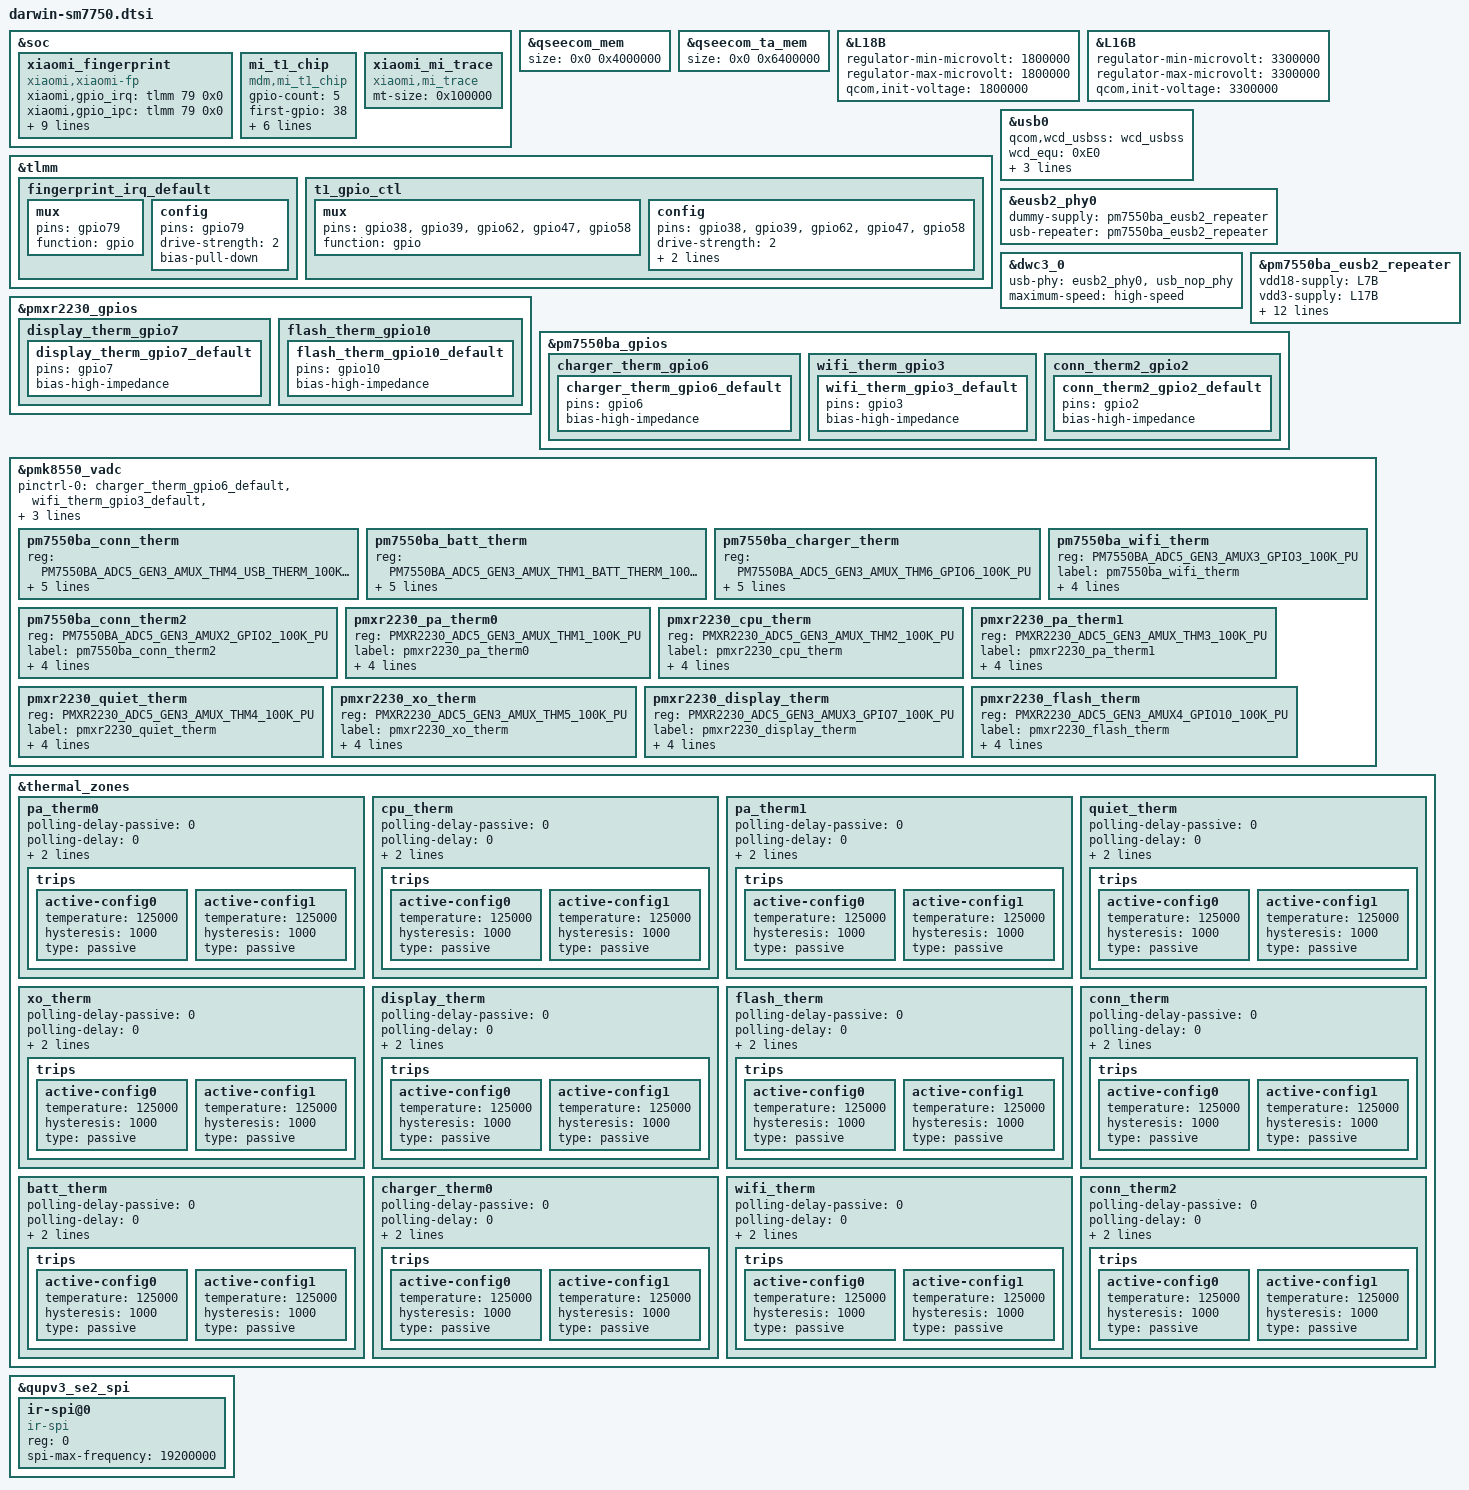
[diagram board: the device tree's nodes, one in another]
/*
  this file is for attribution only of darwin
  And public attribution of xiaomi platforms(like darwin and so on)
*/
#include "darwin-pinctrl.dtsi"
#include "sm7750-xiaomi-common.dtsi"
#include "darwin-charger-common.dtsi"
#include "kera_ufs2.dtsi"
#include <dt-bindings/iio/qcom,spmi-adc5-gen3-pmxr2230.h>

&soc {
    xiaomi_fingerprint {
        compatible = "xiaomi,xiaomi-fp";
        xiaomi,gpio_irq = <&tlmm 79 0x0>;
        xiaomi,gpio_ipc = <&tlmm 79 0x0>;
        xiaomi,vendor_names = "DARWIN_n2_132_431";
        intr2-pin-enable;
        intr2-side-config = "TIC";
        intr2-default-electrical = <1 1>;
        fp_3v3_vreg-supply = <&L16B>;
        fp_1v8_vreg-supply = <&L18B>;
        netlink-event = <25>;
        sensor-loc = <480 1906 719 2165>;
        pinctrl-names = "irq_default";
        pinctrl-0 = <&fingerprint_irq_default>;
        status = "ok";
    };

    mi_t1_chip {
        compatible = "mdm,mi_t1_chip";
        gpio-count = <5>;
        first-gpio = <38>;
        mi-t1-gpio-1 = <&tlmm 38 0x0>;
        mi-t1-gpio-2 = <&tlmm 39 0x0>;
        mi-t1-gpio-3 = <&tlmm 62 0x0>;
        mi-t1-gpio-4 = <&tlmm 47 0x0>;
        mi-t1-gpio-5 = <&tlmm 58 0x0>;
        pinctrl-0 = <&t1_gpio_ctl>;
    };
};

&qseecom_mem {
		size = <0x0 0x4000000>;
};

&qseecom_ta_mem {
		size = <0x0 0x6400000>;
};

&L18B {
    regulator-min-microvolt = <1800000>;
    regulator-max-microvolt = <1800000>;
    qcom,init-voltage = <1800000>;
};

&L16B {
    regulator-min-microvolt = <3300000>;
    regulator-max-microvolt = <3300000>;
    qcom,init-voltage = <3300000>;
};

&tlmm {
    fingerprint_irq_default: fingerprint_irq_default {
        mux {
            pins = "gpio79";
            function = "gpio";
        };
        config {
            pins = "gpio79";
            drive-strength = <2>;
            bias-pull-down;
        };
    };

    /*t1s gpio config*/
    t1_gpio_ctl: t1_gpio_ctl {
        mux {
            pins = "gpio38", "gpio39","gpio62", "gpio47", "gpio58";
            function = "gpio";
        };
        config {
            pins = "gpio38", "gpio39","gpio62", "gpio47", "gpio58";
            drive-strength = <2>;
            bias-disable;
            output-enable;
        };
    };
};

&usb0 {
	qcom,wcd_usbss = <&wcd_usbss>;
	wcd_equ = <0xE0>;
	wcd_equ_global = <0xF0>;
	wcd_equ_host = <0xC0>;
	maximum_speed = "high-speed";
};

&eusb2_phy0 {
	dummy-supply = <&pm7550ba_eusb2_repeater>;
	usb-repeater = <&pm7550ba_eusb2_repeater>;
};

&dwc3_0 {
	usb-phy = <&eusb2_phy0>, <&usb_nop_phy>;
	maximum-speed = "high-speed";
};

&pm7550ba_eusb2_repeater {
	vdd18-supply = <&L7B>;
	vdd3-supply = <&L17B>;
	status = "ok";
	en-carwith = <0>;
	en-storage = <1>;
	qcom,host-param-override-seq =
		<0x00 0x50
		0x0c 0x51
		0x03 0x52
		0x07 0x53
		0x01 0x54
		0x01 0x55
		0x00 0x56
		0x06 0x57
		0x02 0x58
		0x00 0x59
		0x03 0x5a
		0x02 0x5b>;
	qcom,param-override-seq-host-ms =
		<0x00 0x50
		0x00 0x51
		0x01 0x52
		0x07 0x53
		0x05 0x54
		0x00 0x55
		0x03 0x56
		0x00 0x57
		0x02 0x58
		0x00 0x59
		0x03 0x5a
		0x02 0x5b>;
	qcom,param-override-seq =
		<0x00 0x50
		0x0A 0x51
		0x01 0x52
		0x07 0x53
		0x03 0x54
		0x03 0x55
		0x00 0x56
		0x07 0x57
		0x02 0x58
		0x03 0x59
		0x01 0x5a
		0x02 0x5b>;
	qcom,param-override-seq-factory =
		<0x00 0x50
		0x07 0x51
		0x01 0x52
		0x01 0x53
		0x03 0x54
		0x03 0x55
		0x00 0x56
		0x05 0x57
		0x02 0x58
		0x03 0x59
		0x01 0x5a
		0x02 0x5b>;
	qcom,param-override-seq-car =
		<0x00 0x50
		0x07 0x51
		0x01 0x52
		0x01 0x53
		0x03 0x54
		0x03 0x55
		0x00 0x56
		0x05 0x57
		0x02 0x58
		0x03 0x59
		0x01 0x5a
		0x02 0x5b>;
};

&pmxr2230_gpios {
    display_therm_gpio7 {
        display_therm_gpio7_default: display_therm_gpio7_default {
            pins = "gpio7";
            bias-high-impedance;
        };
    };
    flash_therm_gpio10 {
        flash_therm_gpio10_default: flash_therm_gpio10_default {
            pins = "gpio10";
            bias-high-impedance;
        };
    };
};
&pm7550ba_gpios {
    charger_therm_gpio6 {
        charger_therm_gpio6_default: charger_therm_gpio6_default {
            pins = "gpio6";
            bias-high-impedance;
        };
    };
    wifi_therm_gpio3 {
        wifi_therm_gpio3_default: wifi_therm_gpio3_default {
            pins = "gpio3";
            bias-high-impedance;
        };
    };
    conn_therm2_gpio2 {
        conn_therm2_gpio2_default: conn_therm2_gpio2_default {
            pins = "gpio2";
            bias-high-impedance;
        };
    };
};
&pmk8550_vadc {
    pinctrl-names = "default";
    pinctrl-0 = <&charger_therm_gpio6_default &wifi_therm_gpio3_default &conn_therm2_gpio2_default &flash_therm_gpio10_default &display_therm_gpio7_default>;
    pm7550ba_conn_therm {
            reg = <PM7550BA_ADC5_GEN3_AMUX_THM4_USB_THERM_100K_PU>;
            label = "pm7550ba_conn_therm";
            qcom,ratiometric;
            qcom,hw-settle-time = <200>;
            qcom,pre-scaling = <1 1>;
            qcom,adc-tm-type = <1>;
    };
    pm7550ba_batt_therm {
            reg = <PM7550BA_ADC5_GEN3_AMUX_THM1_BATT_THERM_100K_PU>;
            label = "pm7550ba_batt_therm";
            qcom,ratiometric;
            qcom,hw-settle-time = <200>;
            qcom,pre-scaling = <1 1>;
            qcom,adc-tm-type = <1>;
    };
    pm7550ba_charger_therm {
        reg = <PM7550BA_ADC5_GEN3_AMUX_THM6_GPIO6_100K_PU>;
        label = "pm7550ba_charger_therm";
        qcom,ratiometric;
        qcom,hw-settle-time = <200>;
        qcom,pre-scaling = <1 1>;
        qcom,adc-tm-type = <1>;
    };
    pm7550ba_wifi_therm {
        reg = <PM7550BA_ADC5_GEN3_AMUX3_GPIO3_100K_PU>;
        label = "pm7550ba_wifi_therm";
        qcom,ratiometric;
        qcom,hw-settle-time = <200>;
        qcom,pre-scaling = <1 1>;
        qcom,adc-tm-type = <1>;
    };
    pm7550ba_conn_therm2 {
        reg = <PM7550BA_ADC5_GEN3_AMUX2_GPIO2_100K_PU>;
        label = "pm7550ba_conn_therm2";
        qcom,ratiometric;
        qcom,hw-settle-time = <200>;
        qcom,pre-scaling = <1 1>;
        qcom,adc-tm-type = <1>;
    };
    pmxr2230_pa_therm0 {
        reg = <PMXR2230_ADC5_GEN3_AMUX_THM1_100K_PU>;
        label = "pmxr2230_pa_therm0";
        qcom,ratiometric;
        qcom,hw-settle-time = <200>;
        qcom,pre-scaling = <1 1>;
        qcom,adc-tm-type = <1>;
    };
    pmxr2230_cpu_therm {
        reg = <PMXR2230_ADC5_GEN3_AMUX_THM2_100K_PU>;
        label = "pmxr2230_cpu_therm";
        qcom,ratiometric;
        qcom,hw-settle-time = <200>;
        qcom,pre-scaling = <1 1>;
        qcom,adc-tm-type = <1>;
    };
    pmxr2230_pa_therm1 {
        reg = <PMXR2230_ADC5_GEN3_AMUX_THM3_100K_PU>;
        label = "pmxr2230_pa_therm1";
        qcom,ratiometric;
        qcom,hw-settle-time = <200>;
        qcom,pre-scaling = <1 1>;
        qcom,adc-tm-type = <1>;
    };
    pmxr2230_quiet_therm {
        reg = <PMXR2230_ADC5_GEN3_AMUX_THM4_100K_PU>;
        label = "pmxr2230_quiet_therm";
        qcom,ratiometric;
        qcom,hw-settle-time = <200>;
        qcom,pre-scaling = <1 1>;
        qcom,adc-tm-type = <1>;
    };
    pmxr2230_xo_therm {
        reg = <PMXR2230_ADC5_GEN3_AMUX_THM5_100K_PU>;
        label = "pmxr2230_xo_therm";
        qcom,ratiometric;
        qcom,hw-settle-time = <200>;
        qcom,pre-scaling = <1 1>;
        qcom,adc-tm-type = <1>;
    };
    pmxr2230_display_therm {
        reg = <PMXR2230_ADC5_GEN3_AMUX3_GPIO7_100K_PU>;
        label = "pmxr2230_display_therm";
        qcom,ratiometric;
        qcom,hw-settle-time = <200>;
        qcom,pre-scaling = <1 1>;
        qcom,adc-tm-type = <1>;
    };
    pmxr2230_flash_therm {
        reg = <PMXR2230_ADC5_GEN3_AMUX4_GPIO10_100K_PU>;
        label = "pmxr2230_flash_therm";
        qcom,ratiometric;
        qcom,hw-settle-time = <200>;
        qcom,pre-scaling = <1 1>;
        qcom,adc-tm-type = <1>;
    };
};
&thermal_zones {
    pa_therm0 {
        polling-delay-passive = <0>;
        polling-delay = <0>;
        thermal-sensors = <&pmk8550_vadc PMXR2230_ADC5_GEN3_AMUX_THM1_100K_PU>;
        trips {
            active-config0 {
                temperature = <125000>;
                hysteresis = <1000>;
                type = "passive";
            };
            active-config1 {
                temperature = <125000>;
                hysteresis = <1000>;
                type = "passive";
            };
        };
    };
    cpu_therm {
        polling-delay-passive = <0>;
        polling-delay = <0>;
        thermal-sensors = <&pmk8550_vadc PMXR2230_ADC5_GEN3_AMUX_THM2_100K_PU>;
        trips {
            active-config0 {
                temperature = <125000>;
                hysteresis = <1000>;
                type = "passive";
            };
            active-config1 {
                temperature = <125000>;
                hysteresis = <1000>;
                type = "passive";
            };
        };
    };
    pa_therm1 {
        polling-delay-passive = <0>;
        polling-delay = <0>;
        thermal-sensors = <&pmk8550_vadc PMXR2230_ADC5_GEN3_AMUX_THM3_100K_PU>;
        trips {
            active-config0 {
                temperature = <125000>;
                hysteresis = <1000>;
                type = "passive";
            };
            active-config1 {
                temperature = <125000>;
                hysteresis = <1000>;
                type = "passive";
            };
        };
    };
    quiet_therm {
        polling-delay-passive = <0>;
        polling-delay = <0>;
        thermal-sensors = <&pmk8550_vadc PMXR2230_ADC5_GEN3_AMUX_THM4_100K_PU>;
        trips {
            active-config0 {
                temperature = <125000>;
                hysteresis = <1000>;
                type = "passive";
            };
            active-config1 {
                temperature = <125000>;
                hysteresis = <1000>;
                type = "passive";
            };
        };
    };
    xo_therm {
        polling-delay-passive = <0>;
        polling-delay = <0>;
        thermal-sensors = <&pmk8550_vadc PMXR2230_ADC5_GEN3_AMUX_THM5_100K_PU>;
        trips {
            active-config0 {
                temperature = <125000>;
                hysteresis = <1000>;
                type = "passive";
            };
            active-config1 {
                temperature = <125000>;
                hysteresis = <1000>;
                type = "passive";
            };
        };
    };
    display_therm {
        polling-delay-passive = <0>;
        polling-delay = <0>;
        thermal-sensors = <&pmk8550_vadc PMXR2230_ADC5_GEN3_AMUX3_GPIO7_100K_PU>;
        trips {
            active-config0 {
                temperature = <125000>;
                hysteresis = <1000>;
                type = "passive";
            };
            active-config1 {
                temperature = <125000>;
                hysteresis = <1000>;
                type = "passive";
			      };
		    };
    };
    flash_therm {
        polling-delay-passive = <0>;
        polling-delay = <0>;
        thermal-sensors = <&pmk8550_vadc PMXR2230_ADC5_GEN3_AMUX4_GPIO10_100K_PU>;
        trips {
            active-config0 {
                temperature = <125000>;
                hysteresis = <1000>;
                type = "passive";
            };
            active-config1 {
                temperature = <125000>;
                hysteresis = <1000>;
                type = "passive";
			      };
		    };
    };
    conn_therm {
        polling-delay-passive = <0>;
        polling-delay = <0>;
        thermal-sensors = <&pmk8550_vadc PM7550BA_ADC5_GEN3_AMUX_THM4_USB_THERM_100K_PU>;
        trips {
            active-config0 {
                temperature = <125000>;
                hysteresis = <1000>;
                type = "passive";
            };
            active-config1 {
                temperature = <125000>;
                hysteresis = <1000>;
                type = "passive";
            };
        };
    };
    batt_therm {
        polling-delay-passive = <0>;
        polling-delay = <0>;
        thermal-sensors = <&pmk8550_vadc PM7550BA_ADC5_GEN3_AMUX_THM1_BATT_THERM_100K_PU>;
        trips {
            active-config0 {
                temperature = <125000>;
                hysteresis = <1000>;
                type = "passive";
            };
            active-config1 {
                temperature = <125000>;
                hysteresis = <1000>;
                type = "passive";
            };
        };
    };
    charger_therm0 {
        polling-delay-passive = <0>;
        polling-delay = <0>;
        thermal-sensors = <&pmk8550_vadc PM7550BA_ADC5_GEN3_AMUX_THM6_GPIO6_100K_PU>;
        trips {
            active-config0 {
                temperature = <125000>;
                hysteresis = <1000>;
                type = "passive";
            };
            active-config1 {
                temperature = <125000>;
                hysteresis = <1000>;
                type = "passive";
            };
        };
    };
    wifi_therm {
        polling-delay-passive = <0>;
        polling-delay = <0>;
        thermal-sensors = <&pmk8550_vadc PM7550BA_ADC5_GEN3_AMUX3_GPIO3_100K_PU>;
        trips {
            active-config0 {
                temperature = <125000>;
                hysteresis = <1000>;
                type = "passive";
            };
            active-config1 {
                temperature = <125000>;
                hysteresis = <1000>;
                type = "passive";
            };
        };
    };
    conn_therm2 {
        polling-delay-passive = <0>;
        polling-delay = <0>;
        thermal-sensors = <&pmk8550_vadc PM7550BA_ADC5_GEN3_AMUX2_GPIO2_100K_PU>;
        trips {
            active-config0 {
                temperature = <125000>;
                hysteresis = <1000>;
                type = "passive";
            };
            active-config1 {
                temperature = <125000>;
                hysteresis = <1000>;
                type = "passive";
            };
        };
    };
};

&qupv3_se2_spi {
	status = "ok";
	ir-spi@0 {
		compatible = "ir-spi";
		reg = <0>;
		spi-max-frequency = <19200000>;
		status = "ok";
	};
};

&soc {
	xiaomi_mi_trace{
		compatible = "xiaomi,mi_trace";
		mt-size = <0x100000>;
	};
};

